# ior7f701057 register map
Registers from a debugger description file.
Registers are 8-bit, access not given, no defined reset value unless marked. A register's access mark holds for its fields unless they carry their own. Addresses are absolute; registers are grouped by the start of their names; lines under a group give offsets from that group; [hi:lo] are bit positions; {n}, {i} and the like mark numbered series; 'fields as' and 'values as' point back to an identical list; <NAME> marks a mode.

## SELB
0xFFBC0100 SELB_TAUJ0I
0xFFBC0200 SELB_TAUD0I 16-bit
0xFFBC0300 SELB_INTC1 16-bit
0xFFBC0304 SELB_INTC2 16-bit
0xFFBC0600 SELB_READTEST

## FCLA0CTL0
0xFFC34000 FCLA0CTL0_NMI
0xFFC34020 FCLA0CTL0_INTPL
0xFFC34040 FCLA0CTL0_INTPH
0xFFC34060 FCLA0CTL0_ADC0
0xFFC34080 FCLA0CTL0_ADC1

## FCLA0CTL1
0xFFC34024 FCLA0CTL1_INTPL
0xFFC34044 FCLA0CTL1_INTPH
0xFFC34064 FCLA0CTL1_ADC0
0xFFC34084 FCLA0CTL1_ADC1

## FCLA0CTL2
0xFFC34028 FCLA0CTL2_INTPL
0xFFC34048 FCLA0CTL2_INTPH
0xFFC34068 FCLA0CTL2_ADC0
0xFFC34088 FCLA0CTL2_ADC1

## FCLA0CTL3
0xFFC3402C FCLA0CTL3_INTPL
0xFFC3404C FCLA0CTL3_INTPH

## FCLA0CTL4
0xFFC34030 FCLA0CTL4_INTPL
0xFFC34050 FCLA0CTL4_INTPH

## FCLA0CTL5
0xFFC34034 FCLA0CTL5_INTPL
0xFFC34054 FCLA0CTL5_INTPH

## FCLA0CTL6
0xFFC34038 FCLA0CTL6_INTPL
0xFFC34058 FCLA0CTL6_INTPH

## FCLA0CTL7
0xFFC3403C FCLA0CTL7_INTPL
0xFFC3405C FCLA0CTL7_INTPH

## CKSC
0xFFF82000 CKSC_AWDTAD_CTL 32-bit
0xFFF82008 CKSC_AWDTAD_ACT 32-bit ro
0xFFF82018 CKSC_AWDTAD_STPM 32-bit
0xFFF82100 CKSC_ATAUJS_CTL 32-bit
0xFFF82108 CKSC_ATAUJS_ACT 32-bit ro
0xFFF82200 CKSC_ATAUJD_CTL 32-bit
0xFFF82208 CKSC_ATAUJD_ACT 32-bit ro
0xFFF82218 CKSC_ATAUJD_STPM 32-bit
0xFFF82300 CKSC_ARTCAS_CTL 32-bit
0xFFF82308 CKSC_ARTCAS_ACT 32-bit ro
0xFFF82400 CKSC_ARTCAD_CTL 32-bit
0xFFF82408 CKSC_ARTCAD_ACT 32-bit ro
0xFFF82418 CKSC_ARTCAD_STPM 32-bit
0xFFF82500 CKSC_AADCAS_CTL 32-bit
0xFFF82508 CKSC_AADCAS_ACT 32-bit ro
0xFFF82600 CKSC_AADCAD_CTL 32-bit
0xFFF82608 CKSC_AADCAD_ACT 32-bit ro
0xFFF82618 CKSC_AADCAD_STPM 32-bit
0xFFF82700 CKSC_AFOUTS_CTL 32-bit
0xFFF82708 CKSC_AFOUTS_ACT 32-bit ro
0xFFF82718 CKSC_AFOUTS_STPM 32-bit
0xFFF8A000 CKSC_CPUCLKS_CTL 32-bit
0xFFF8A008 CKSC_CPUCLKS_ACT 32-bit ro
0xFFF8A100 CKSC_CPUCLKD_CTL 32-bit
0xFFF8A108 CKSC_CPUCLKD_ACT 32-bit ro
0xFFF8A200 CKSC_IPERI1S_CTL 32-bit
0xFFF8A208 CKSC_IPERI1S_ACT 32-bit ro
0xFFF8A300 CKSC_IPERI2S_CTL 32-bit
0xFFF8A308 CKSC_IPERI2S_ACT 32-bit ro
0xFFF8A400 CKSC_ILINS_CTL 32-bit
0xFFF8A408 CKSC_ILINS_ACT 32-bit ro
0xFFF8A500 CKSC_IADCAS_CTL 32-bit
0xFFF8A508 CKSC_IADCAS_ACT 32-bit ro
0xFFF8A600 CKSC_IADCAD_CTL 32-bit
0xFFF8A608 CKSC_IADCAD_ACT 32-bit ro
0xFFF8A800 CKSC_ILIND_CTL 32-bit
0xFFF8A808 CKSC_ILIND_ACT 32-bit ro
0xFFF8A818 CKSC_ILIND_STPM 32-bit
0xFFF8A900 CKSC_ICANS_CTL 32-bit
0xFFF8A908 CKSC_ICANS_ACT 32-bit ro
0xFFF8A918 CKSC_ICANS_STPM 32-bit
0xFFF8AA00 CKSC_ICANOSCD_CTL 32-bit
0xFFF8AA08 CKSC_ICANOSCD_ACT 32-bit ro
0xFFF8AA18 CKSC_ICANOSCD_STPM 32-bit
0xFFF8AB00 CKSC_ICSIS_CTL 32-bit
0xFFF8AB08 CKSC_ICSIS_ACT 32-bit ro

## SEG
0xFFFF8C00 SEG_CONT 16-bit
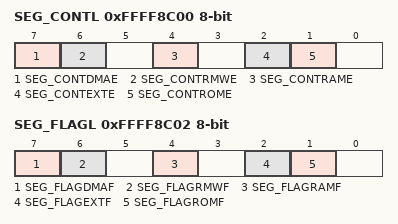
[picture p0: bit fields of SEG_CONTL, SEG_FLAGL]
0xFFFF8C00 SEG_CONTL
  [7] SEG_CONTDMAE, [6] SEG_CONTRMWE, [4] SEG_CONTRAME, [2] SEG_CONTEXTE, [1] SEG_CONTROME
0xFFFF8C02 SEG_FLAG 16-bit
0xFFFF8C02 SEG_FLAGL
  [7] SEG_FLAGDMAF, [6] SEG_FLAGRMWF, [4] SEG_FLAGRAMF, [2] SEG_FLAGEXTF, [1] SEG_FLAGROMF

## Notices in the file
Copyright(C) 2015 Renesas
